# GD32G5x3 register map
File version: 1.0
CPU: CM33 r2p1, little endian, MPU, FPU, 4 interrupt priority bits
Registers are 32-bit, read-write, reset 0x0 unless marked. A register's access mark holds for its fields unless they carry their own. Offsets are from the block's base; [hi:lo] are bit positions; {n}, {i} and the like mark numbered series; 'fields as' and 'values as' point back to an identical list.

## TIMER5 — Basic timer
Base 0x40001000
Same registers: TIMER6 0x40001400
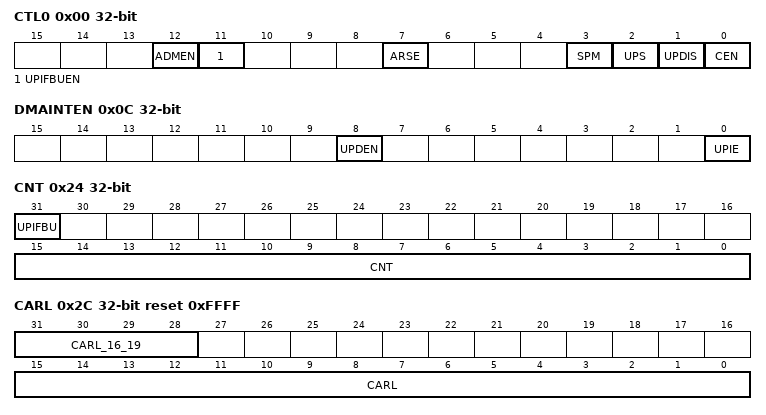
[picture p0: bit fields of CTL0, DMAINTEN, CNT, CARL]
0x00 CTL0 — Control register 0
  [12] ADMEN — Adjustment mode enable
  [11] UPIFBUEN — UPIF bit backup enable
  [7] ARSE — Auto-reload shadow enable
  [3] SPM — Single pulse mode
  [2] UPS — Update source
  [1] UPDIS — Update disable
  [0] CEN — Counter enable
0x04 CTL1 — Control register 1
  [6:4] MMC0 — Master mode control 0
0x0C DMAINTEN — Interrupt enable register
  [8] UPDEN — Update DMA request enable
  [0] UPIE — Update interrupt enable
0x10 INTF — Interrupt flag register
  [0] UPIF — Update interrupt flag
0x14 SWEVG wo — Software event generation register
  [0] UPG — Update generation
0x24 CNT access per field — Counter register
  [31] UPIFBU ro — UPIF bit backup
  [15:0] CNT rw — This bit-field indicates the current counter value
0x28 PSC — Prescaler register
  [15:0] PSC — Prescaler value of the counter clock
0x2C CARL reset 0xFFFF — Counter auto reload register
  [31:28] CARL_16_19 — Counter auto reload value(bit 16 to 19)
  [15:0] CARL — Counter auto reload value

## TMU — Trigonometric Math Unit
Base 0x48024400
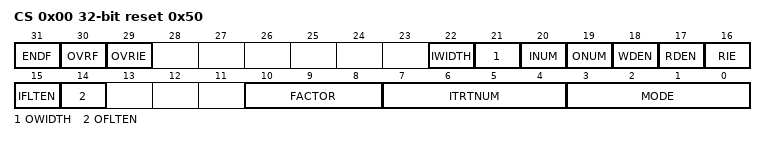
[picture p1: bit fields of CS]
0x00 CS access per field reset 0x50 — Control and status register
  [31] ENDF ro — End of TMU operation flag
  [30] OVRF rw — The flag of overflow
  [29] OVRIE rw — Overflow interrupt enable
  [22] IWIDTH rw — Width of input data
  [21] OWIDTH rw — Width of output data
  [20] INUM rw — The number of times that the TMU_IDATA needs to be written
  [19] ONUM rw — The number of times that the TMU_ODATA needs to be read
  [18] WDEN rw — Enable DMA request to write TMU_IDATA
  [17] RDEN rw — Enable DMA request to read TMU_ODATA
  [16] RIE rw — Enable interrupt request to read TMU_ODATA
  [15] IFLTEN rw — Input floating point format enable
  [14] OFLTEN rw — Output floating point format enable
  [10:8] FACTOR rw — Scaling factor
  [7:4] ITRTNUM rw — Number of iterations
  [3:0] MODE rw — Mode of TMU operation
0x04 IDATA wo — Input data register
  [31:0] IDATA — The input data
0x08 ODATA ro — Output data register
  [31:0] ODATA — The output data

## TRIGSEL — Trigger selection controller
Base 0x40018400
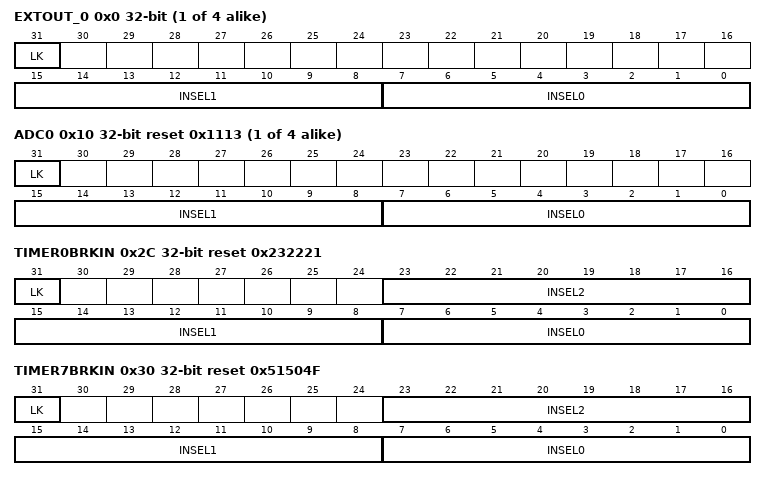
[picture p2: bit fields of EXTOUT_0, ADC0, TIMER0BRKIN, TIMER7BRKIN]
{0x0+4i} EXTOUT_{i} (i=0..3) — Trigger selection for EXTOUT register {i}
  [31] LK — TRIGSEL register lock
  [15:8] INSEL1 — Trigger input source selection for output1
  [7:0] INSEL0 — Trigger input source selection for output0
{0x10+4i} ADC{i} reset 0x1113 (i=0..3) — Trigger selection for ADC{i} register
  fields as EXTOUT_0
0x2C TIMER0BRKIN reset 0x232221 — Trigger selection for TIMER0_BRKIN register
  [31] LK — TRIGSEL register lock
  [23:16] INSEL2 — Trigger input source selection for output2
  [15:8] INSEL1 — Trigger input source selection for output1
  [7:0] INSEL0 — Trigger input source selection for output0
0x30 TIMER7BRKIN reset 0x51504F — Trigger selection for TIMER7_BRKIN register
  fields as TIMER0BRKIN
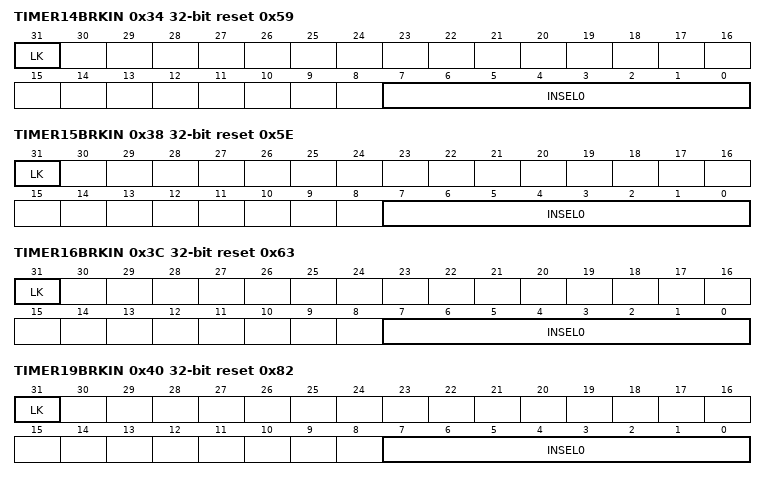
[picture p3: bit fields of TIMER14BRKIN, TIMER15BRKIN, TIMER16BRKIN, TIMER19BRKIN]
0x34 TIMER14BRKIN reset 0x59 — Trigger selection for TIMER14_BRKIN register
  [31] LK — TRIGSEL register lock
  [7:0] INSEL0 — Trigger input source selection for output0
0x38 TIMER15BRKIN reset 0x5E — Trigger selection for TIMER15_BRKIN register
  fields as TIMER14BRKIN
0x3C TIMER16BRKIN reset 0x63 — Trigger selection for TIMER16_BRKIN register
  fields as TIMER14BRKIN
0x40 TIMER19BRKIN reset 0x82 — Trigger selection for TIMER19_BRKIN register
  fields as TIMER14BRKIN
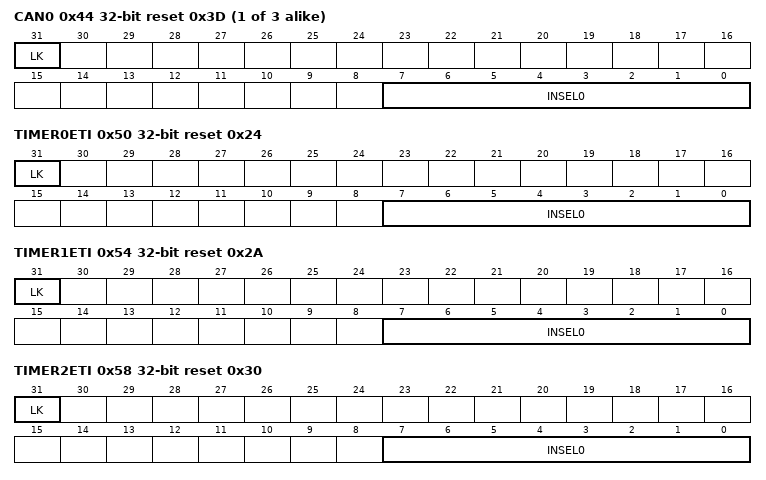
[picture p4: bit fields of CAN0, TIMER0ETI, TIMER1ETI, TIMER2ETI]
{0x44+4i} CAN{i} reset 0x3D (i=0..2) — Trigger selection for CAN{i} register
  fields as TIMER14BRKIN
0x50 TIMER0ETI reset 0x24 — Trigger selection for TIMER0_ETI register
  fields as TIMER14BRKIN
0x54 TIMER1ETI reset 0x2A — Trigger selection for TIMER1_ETI register
  fields as TIMER14BRKIN
0x58 TIMER2ETI reset 0x30 — Trigger selection for TIMER2_ETI register
  fields as TIMER14BRKIN
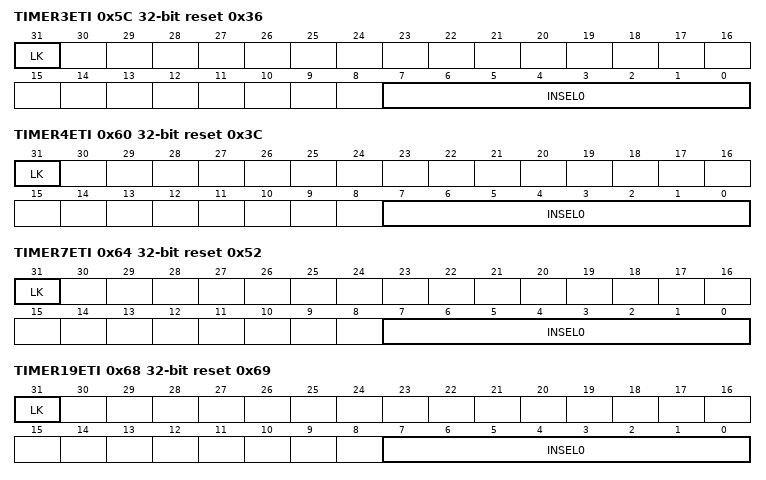
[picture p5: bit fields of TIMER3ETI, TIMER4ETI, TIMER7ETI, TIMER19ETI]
0x5C TIMER3ETI reset 0x36 — Trigger selection for TIMER3_ETI register
  fields as TIMER14BRKIN
0x60 TIMER4ETI reset 0x3C — Trigger selection for TIMER4_ETI register
  fields as TIMER14BRKIN
0x64 TIMER7ETI reset 0x52 — Trigger selection for TIMER7_ETI register
  fields as TIMER14BRKIN
0x68 TIMER19ETI reset 0x69 — Trigger selection for TIMER19_ETI register
  fields as TIMER14BRKIN
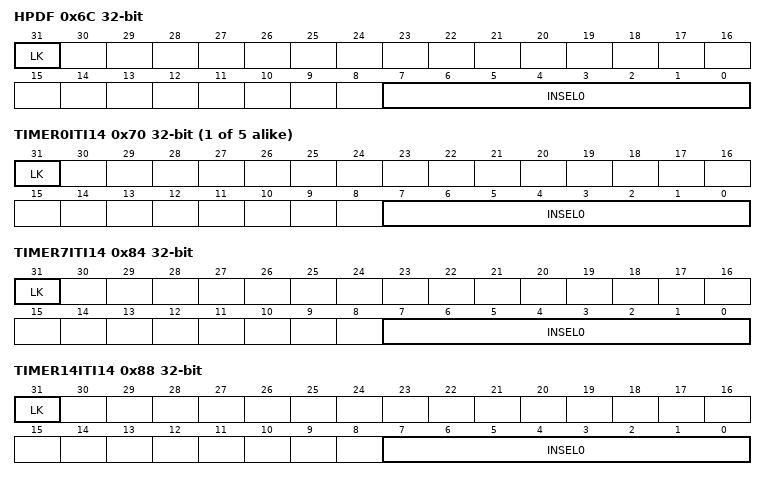
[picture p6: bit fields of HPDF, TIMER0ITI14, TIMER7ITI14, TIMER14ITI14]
0x6C HPDF — Trigger selection for HPDF_ITRG register
  fields as TIMER14BRKIN
{0x70+4i} TIMER{i}ITI14 (i=0..4) — Trigger selection for TIMER{i}_ITI14 register
  fields as TIMER14BRKIN
0x84 TIMER7ITI14 — Trigger selection for TIMER7_ITI14 register
  fields as TIMER14BRKIN
0x88 TIMER14ITI14 — Trigger selection for TIMER14_ITI14 register
  fields as TIMER14BRKIN
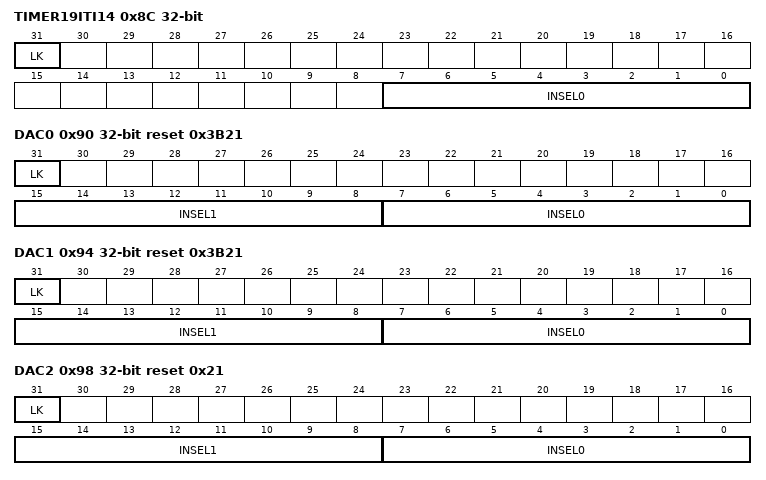
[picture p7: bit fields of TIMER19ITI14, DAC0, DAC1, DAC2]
0x8C TIMER19ITI14 — Trigger selection for TIMER19_ITI14 register
  fields as TIMER14BRKIN
0x90 DAC0 reset 0x3B21 — Trigger selection for DAC0 register
  fields as EXTOUT_0
0x94 DAC1 reset 0x3B21 — Trigger selection for DAC1 register
  fields as EXTOUT_0
0x98 DAC2 reset 0x21 — Trigger selection for DAC2 register
  fields as EXTOUT_0
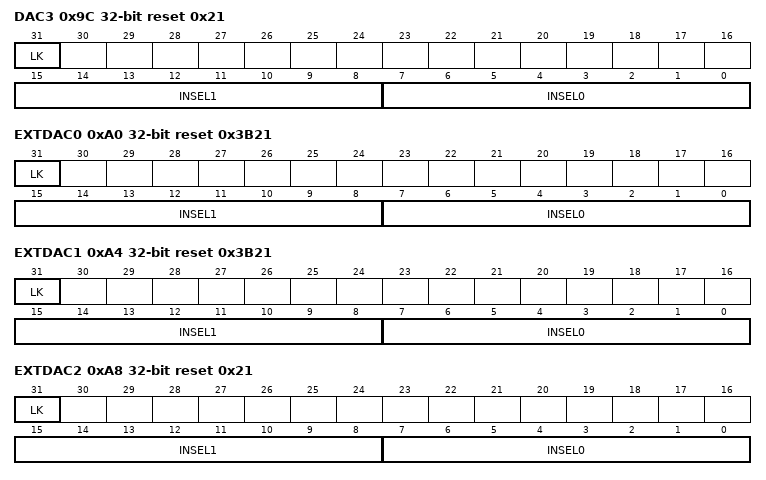
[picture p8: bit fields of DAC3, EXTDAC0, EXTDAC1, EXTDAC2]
0x9C DAC3 reset 0x21 — Trigger selection for DAC3 register
  fields as EXTOUT_0
0xA0 EXTDAC0 reset 0x3B21 — Trigger selection for DAC0 extended register
  fields as EXTOUT_0
0xA4 EXTDAC1 reset 0x3B21 — Trigger selection for DAC1 extended register
  fields as EXTOUT_0
0xA8 EXTDAC2 reset 0x21 — Trigger selection for DAC2 extended register
  fields as EXTOUT_0
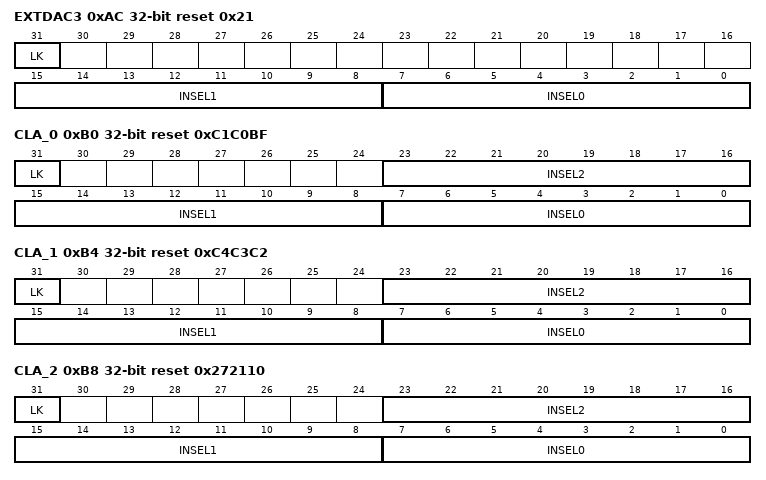
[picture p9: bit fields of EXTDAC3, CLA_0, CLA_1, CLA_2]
0xAC EXTDAC3 reset 0x21 — Trigger selection for DAC3 extended register
  fields as EXTOUT_0
0xB0 CLA_0 reset 0xC1C0BF — Trigger selection for CLA register 0
  fields as TIMER0BRKIN
0xB4 CLA_1 reset 0xC4C3C2 — Trigger selection for CLA register 1
  fields as TIMER0BRKIN
0xB8 CLA_2 reset 0x272110 — Trigger selection for CLA register 2
  fields as TIMER0BRKIN
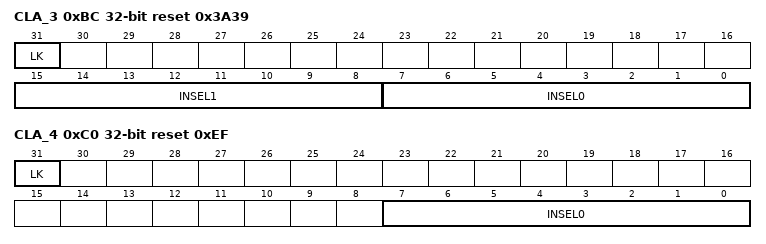
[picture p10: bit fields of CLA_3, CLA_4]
0xBC CLA_3 reset 0x3A39 — Trigger selection for CLA register 3
  fields as EXTOUT_0
0xC0 CLA_4 reset 0xEF — Trigger selection for CLA register 4
  fields as TIMER14BRKIN

## TRNG — True random number generator
Base 0x48021800
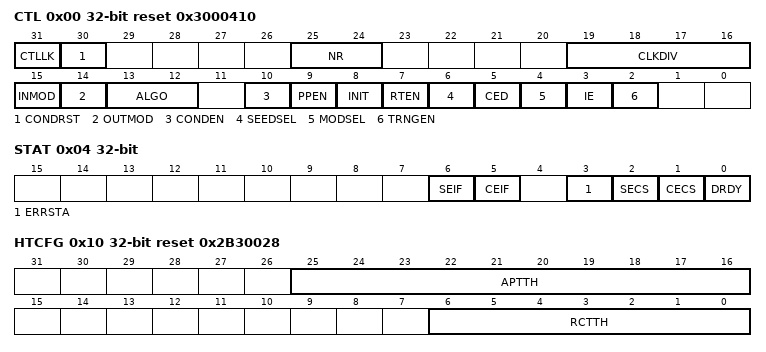
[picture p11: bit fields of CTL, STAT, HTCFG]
0x00 CTL reset 0x3000410 — Control register
  [31] CTLLK — TRNG_CTL register lock bit
  [30] CONDRST — Reset conditioning logic
  [25:24] NR — Analog trng power mode
  [19:16] CLKDIV — TRNG clock divider
  [15] INMOD — Select random seed number input to conditioning module
  [14] OUTMOD — Select random data width output of conditioning module
  [13:12] ALGO — conditioning module hash algorithm selection
  [10] CONDEN — The enable bit of conditioning component
  [9] PPEN — The enable bit of post processing function
  [8] INIT — Initialize hash algorithm when conditioning enabled
  [7] RTEN — Replace test enable bit
  [6] SEEDSEL — seed mode selection
  [5] CED — Clock error detection
  [4] MODSEL — LFSR or NIST mode selection
  [3] IE — The enable bit of the TRNG interrupt
  [2] TRNGEN — The enabled bit of the TRNG
0x04 STAT access per field — Status register
  [6] SEIF rw — Seed error interrupt flag
  [5] CEIF rw — Clock error interrupt flag
  [3] ERRSTA ro — NIST mode error flag, this bit could be reset by CONDRST
  [2] SECS ro — Seed error current status
  [1] CECS ro — Clock error current status
  [0] DRDY ro — Random data ready status bit
0x08 DATA ro
  [31:0] TRNDATA — 32-bit random data
0x10 HTCFG reset 0x2B30028 — Health tests configure register
  [25:16] APTTH — Adaptive proportion test threshold
  [6:0] RCTTH — Repetition count test threshold

## VREF
Base 0x40017800
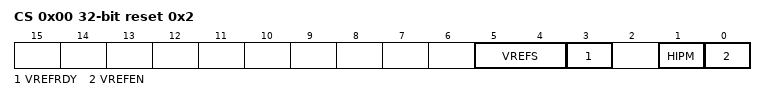
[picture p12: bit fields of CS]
0x00 CS access per field reset 0x2 — Control and status register
  [5:4] VREFS rw — Voltage reference select
  [3] VREFRDY ro — VREF ready
  [1] HIPM rw — High impedance mode
  [0] VREFEN rw — VREF enable
0x04 CALIB — Calibration register
  [5:0] VREFCAL — VREF calibration

## WWDGT — Window watchdog timer
Base 0x40002C00
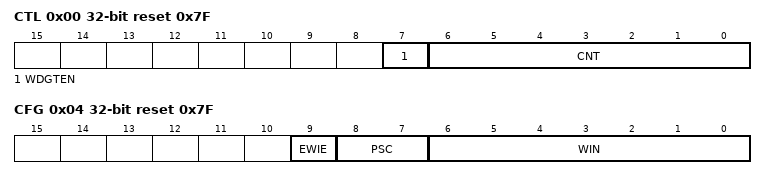
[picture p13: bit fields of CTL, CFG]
0x00 CTL reset 0x7F — Control register
  [7] WDGTEN — Activation bit
  [6:0] CNT — 7-bit counter
0x04 CFG reset 0x7F — Configuration register
  [9] EWIE — Early wakeup interrupt
  [8:7] PSC — Prescaler
  [6:0] WIN — 7-bit window value
0x08 STAT — Status register
  [0] EWIF — Early wakeup interrupt flag
